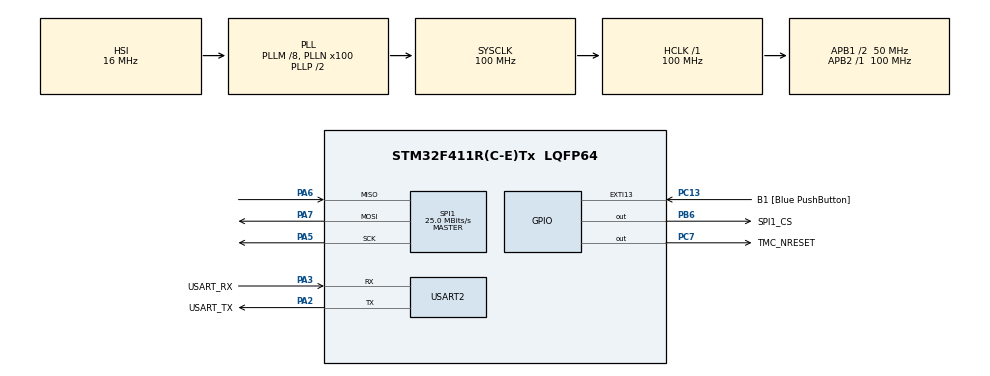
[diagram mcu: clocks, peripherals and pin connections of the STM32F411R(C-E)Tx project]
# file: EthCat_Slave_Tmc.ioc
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Dma.Request0=SPI1_RX
Dma.Request1=SPI1_TX
Dma.SPI1_RX.0.Direction=DMA_PERIPH_TO_MEMORY
Dma.SPI1_RX.0.FIFOMode=DMA_FIFOMODE_ENABLE
Dma.SPI1_RX.0.FIFOThreshold=DMA_FIFO_THRESHOLD_FULL
Dma.SPI1_RX.0.Instance=DMA2_Stream0
Dma.SPI1_RX.0.MemBurst=DMA_MBURST_SINGLE
Dma.SPI1_RX.0.MemDataAlignment=DMA_MDATAALIGN_BYTE
Dma.SPI1_RX.0.MemInc=DMA_MINC_ENABLE
Dma.SPI1_RX.0.Mode=DMA_NORMAL
Dma.SPI1_RX.0.PeriphBurst=DMA_PBURST_SINGLE
Dma.SPI1_RX.0.PeriphDataAlignment=DMA_PDATAALIGN_BYTE
Dma.SPI1_RX.0.PeriphInc=DMA_PINC_DISABLE
Dma.SPI1_RX.0.Priority=DMA_PRIORITY_HIGH
Dma.SPI1_TX.1.Direction=DMA_MEMORY_TO_PERIPH
Dma.SPI1_TX.1.FIFOMode=DMA_FIFOMODE_ENABLE
Dma.SPI1_TX.1.FIFOThreshold=DMA_FIFO_THRESHOLD_FULL
Dma.SPI1_TX.1.Instance=DMA2_Stream2
Dma.SPI1_TX.1.MemBurst=DMA_MBURST_SINGLE
Dma.SPI1_TX.1.MemDataAlignment=DMA_MDATAALIGN_BYTE
Dma.SPI1_TX.1.MemInc=DMA_MINC_ENABLE
Dma.SPI1_TX.1.Mode=DMA_NORMAL
Dma.SPI1_TX.1.PeriphBurst=DMA_PBURST_SINGLE
Dma.SPI1_TX.1.PeriphDataAlignment=DMA_PDATAALIGN_BYTE
Dma.SPI1_TX.1.PeriphInc=DMA_PINC_DISABLE
Dma.SPI1_TX.1.Priority=DMA_PRIORITY_HIGH
FREERTOS.INCLUDE_eTaskGetState=0
FREERTOS.INCLUDE_pcTaskGetTaskName=1
FREERTOS.INCLUDE_vTaskDelayUntil=1
FREERTOS.INCLUDE_xEventGroupSetBitFromISR=1
FREERTOS.INCLUDE_xTimerPendFunctionCall=1
FREERTOS.Tasks01=appTestTask,0,256,testTask,As weak,NULL,Dynamic,NULL,NULL;ethCatSlvTask,2,1024,ethCat_Task,As weak,NULL,Dynamic,NULL,NULL
FREERTOS.configCHECK_FOR_STACK_OVERFLOW=1
FREERTOS.configENABLE_FPU=1
FREERTOS.configGENERATE_RUN_TIME_STATS=1
FREERTOS.configUSE_IDLE_HOOK=1
FREERTOS.configUSE_NEWLIB_REENTRANT=1
FREERTOS.configUSE_TICKLESS_IDLE=1
FREERTOS.configUSE_TIMERS=1
Mcu.Family=STM32F4
Mcu.Name=STM32F411R(C-E)Tx
Mcu.Package=LQFP64
NVIC.DMA2_Stream0_IRQn=true\:5\:0\:false\:false\:true\:true\:false\:true\:true
NVIC.DMA2_Stream2_IRQn=true\:5\:0\:false\:false\:true\:true\:false\:true\:true
NVIC.PriorityGroup=NVIC_PRIORITYGROUP_4
NVIC.SPI1_IRQn=true\:5\:0\:false\:false\:true\:true\:true\:true\:true
NVIC.TIM1_UP_TIM10_IRQn=true\:15\:0\:false\:false\:true\:false\:false\:true\:true
NVIC.TimeBase=TIM1_UP_TIM10_IRQn
NVIC.TimeBaseIP=TIM1
PA13.GPIO_Label=TMS
PA13.Mode=Serial_Wire
PA13.Signal=SYS_JTMS-SWDIO
PA14.GPIO_Label=TCK
PA14.Mode=Serial_Wire
PA14.Signal=SYS_JTCK-SWCLK
PA2.GPIO_Label=USART_TX
PA2.Mode=Asynchronous
PA2.Signal=USART2_TX
PA3.GPIO_Label=USART_RX
PA3.Mode=Asynchronous
PA3.Signal=USART2_RX
PA5.Mode=Full_Duplex_Master
PA5.Signal=SPI1_SCK
PA6.Mode=Full_Duplex_Master
PA6.Signal=SPI1_MISO
PA7.Mode=Full_Duplex_Master
PA7.Signal=SPI1_MOSI
PB6.GPIO_Label=SPI1_CS
PB6.GPIO_PuPd=GPIO_PULLUP
PB6.GPIO_Speed=GPIO_SPEED_FREQ_LOW
PB6.Signal=GPIO_Output
PC13-ANTI_TAMP.GPIO_Label=B1 [Blue PushButton]
PC13-ANTI_TAMP.GPIO_ModeDefaultEXTI=GPIO_MODE_IT_FALLING
PC13-ANTI_TAMP.Signal=GPXTI13
PC14-OSC32_IN.Mode=LSE-External-Oscillator
PC14-OSC32_IN.Signal=RCC_OSC32_IN
PC15-OSC32_OUT.Mode=LSE-External-Oscillator
PC15-OSC32_OUT.Signal=RCC_OSC32_OUT
PC7.GPIO_Label=TMC_NRESET
PC7.GPIO_ModeDefaultOutputPP=GPIO_MODE_OUTPUT_PP
PC7.GPIO_PuPd=GPIO_PULLUP
PC7.GPIO_Speed=GPIO_SPEED_FREQ_MEDIUM
PC7.Signal=GPIO_Output
PH0\ -\ OSC_IN.Mode=HSE-External-Clock-Source
PH0\ -\ OSC_IN.Signal=RCC_OSC_IN
PH1\ -\ OSC_OUT.Mode=HSE-External-Clock-Source
PH1\ -\ OSC_OUT.Signal=RCC_OSC_OUT
ProjectManager.HeapSize=0x200
ProjectManager.StackSize=0x400
ProjectManager.TargetToolchain=STM32CubeIDE
RCC.48MHZClocksFreq_Value=50000000
RCC.AHBFreq_Value=100000000
RCC.APB1CLKDivider=RCC_HCLK_DIV2
RCC.APB1Freq_Value=50000000
RCC.APB1TimFreq_Value=100000000
RCC.APB2Freq_Value=100000000
RCC.APB2TimFreq_Value=100000000
RCC.CortexFreq_Value=100000000
RCC.FLatency-AdvancedSettings=FLASH_LATENCY_3
RCC.HCLKFreq_Value=100000000
RCC.HSE_VALUE=8000000
RCC.HSI_VALUE=16000000
RCC.PLLM=8
RCC.PLLN=100
RCC.SYSCLKFreq_VALUE=100000000
RCC.SYSCLKSource=RCC_SYSCLKSOURCE_PLLCLK
RCC.VCOOutputFreq_Value=200000000
SPI1.BaudRatePrescaler=SPI_BAUDRATEPRESCALER_4
SPI1.CLKPhase=SPI_PHASE_2EDGE
SPI1.CLKPolarity=SPI_POLARITY_HIGH
SPI1.CalculateBaudRate=25.0 MBits/s
SPI1.Direction=SPI_DIRECTION_2LINES
SPI1.Mode=SPI_MODE_MASTER
SPI1.VirtualType=VM_MASTER
USART2.VirtualMode=VM_ASYNC
VP_FREERTOS_VS_CMSIS_V1.Mode=CMSIS_V1
VP_SYS_VS_tim1.Mode=TIM1
board=NUCLEO-F411RE

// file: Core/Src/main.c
/* USER CODE BEGIN Header */
/**
  ******************************************************************************
  * @file           : main.c
  * @brief          : Main program body
  ******************************************************************************
  * @attention
  *
  * Copyright (c) 2023 STMicroelectronics.
  * All rights reserved.
  *
  * This software is licensed under terms that can be found in the LICENSE file
  * in the root directory of this software component.
  * If no LICENSE file comes with this software, it is provided AS-IS.
  *
  ******************************************************************************
  */
/* USER CODE END Header */
#include "main.h"
#include "cmsis_os.h"
#include "dma.h"
#include "spi.h"
#include "usart.h"
#include "gpio.h"

/* USER CODE BEGIN Includes */
#include "TMC8462.h"
/* USER CODE END Includes */

void SystemClock_Config(void);
void MX_FREERTOS_Init(void);

int main(void)
{

  /* MCU Configuration--------------------------------------------------------*/

  /* Reset of all peripherals, Initializes the Flash interface and the Systick. */
  HAL_Init();

  /* Configure the system clock */
  SystemClock_Config();

  /* Initialize all configured peripherals */
  MX_GPIO_Init();
  MX_DMA_Init();
  MX_SPI1_Init();
  MX_USART2_UART_Init();

  /* Call init function for freertos objects (in freertos.c) */
  MX_FREERTOS_Init();

  /* Start scheduler */
  osKernelStart();
  /* We should never get here as control is now taken by the scheduler */
  /* Infinite loop */
  while (1)
  {

  }
}

void SystemClock_Config(void)
{
  RCC_OscInitTypeDef RCC_OscInitStruct = {0};
  RCC_ClkInitTypeDef RCC_ClkInitStruct = {0};

  /** Configure the main internal regulator output voltage
  */
  __HAL_RCC_PWR_CLK_ENABLE();
  __HAL_PWR_VOLTAGESCALING_CONFIG(PWR_REGULATOR_VOLTAGE_SCALE1);

  /** Initializes the RCC Oscillators according to the specified parameters
  * in the RCC_OscInitTypeDef structure.
  */
  RCC_OscInitStruct.OscillatorType = RCC_OSCILLATORTYPE_HSI;
  RCC_OscInitStruct.HSIState = RCC_HSI_ON;
  RCC_OscInitStruct.HSICalibrationValue = RCC_HSICALIBRATION_DEFAULT;
  RCC_OscInitStruct.PLL.PLLState = RCC_PLL_ON;
  RCC_OscInitStruct.PLL.PLLSource = RCC_PLLSOURCE_HSI;
  RCC_OscInitStruct.PLL.PLLM = 8;
  RCC_OscInitStruct.PLL.PLLN = 100;
  RCC_OscInitStruct.PLL.PLLP = RCC_PLLP_DIV2;
  RCC_OscInitStruct.PLL.PLLQ = 4;
  if (HAL_RCC_OscConfig(&RCC_OscInitStruct) != HAL_OK)
  {
    Error_Handler();
  }

  /** Initializes the CPU, AHB and APB buses clocks
  */
  RCC_ClkInitStruct.ClockType = RCC_CLOCKTYPE_HCLK|RCC_CLOCKTYPE_SYSCLK
                              |RCC_CLOCKTYPE_PCLK1|RCC_CLOCKTYPE_PCLK2;
  RCC_ClkInitStruct.SYSCLKSource = RCC_SYSCLKSOURCE_PLLCLK;
  RCC_ClkInitStruct.AHBCLKDivider = RCC_SYSCLK_DIV1;
  RCC_ClkInitStruct.APB1CLKDivider = RCC_HCLK_DIV2;
  RCC_ClkInitStruct.APB2CLKDivider = RCC_HCLK_DIV1;

  if (HAL_RCC_ClockConfig(&RCC_ClkInitStruct, FLASH_LATENCY_3) != HAL_OK)
  {
    Error_Handler();
  }
}

void HAL_TIM_PeriodElapsedCallback(TIM_HandleTypeDef *htim)
{
  if (htim->Instance == TIM1) {
    HAL_IncTick();
  }
}

void Error_Handler(void)
{
  __disable_irq();
  while (1)
  {
  }
}

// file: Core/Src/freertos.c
/* USER CODE BEGIN Header */
/**
  ******************************************************************************
  * File Name          : freertos.c
  * Description        : Code for freertos applications
  ******************************************************************************
  * @attention
  *
  * Copyright (c) 2023 STMicroelectronics.
  * All rights reserved.
  *
  * This software is licensed under terms that can be found in the LICENSE file
  * in the root directory of this software component.
  * If no LICENSE file comes with this software, it is provided AS-IS.
  *
  ******************************************************************************
  */
/* USER CODE END Header */

#include "FreeRTOS.h"
#include "task.h"
#include "main.h"
#include "cmsis_os.h"

/* USER CODE BEGIN Includes */

#include "appTest.h"

/* USER CODE END Includes */

osThreadId appTestTaskHandle;
osThreadId ethCatSlvTaskHandle;

void testTask(void const * argument);
void ethCat_Task(void const * argument);

void MX_FREERTOS_Init(void); /* (MISRA C 2004 rule 8.1) */

/* GetIdleTaskMemory prototype (linked to static allocation support) */
void vApplicationGetIdleTaskMemory( StaticTask_t **ppxIdleTaskTCBBuffer, StackType_t **ppxIdleTaskStackBuffer, uint32_t *pulIdleTaskStackSize );

/* GetTimerTaskMemory prototype (linked to static allocation support) */
void vApplicationGetTimerTaskMemory( StaticTask_t **ppxTimerTaskTCBBuffer, StackType_t **ppxTimerTaskStackBuffer, uint32_t *pulTimerTaskStackSize );

/* Hook prototypes */
void configureTimerForRunTimeStats(void);
unsigned long getRunTimeCounterValue(void);
void vApplicationIdleHook(void);
void vApplicationStackOverflowHook(xTaskHandle xTask, signed char *pcTaskName);

/* USER CODE BEGIN 1 */
/* Functions needed when configGENERATE_RUN_TIME_STATS is on */
__weak void configureTimerForRunTimeStats(void)
{

}

__weak unsigned long getRunTimeCounterValue(void)
{
return 0;
}
/* USER CODE END 1 */

/* USER CODE BEGIN 2 */
__weak void vApplicationIdleHook( void )
{
   /* vApplicationIdleHook() will only be called if configUSE_IDLE_HOOK is set
   to 1 in FreeRTOSConfig.h. It will be called on each iteration of the idle
   task. It is essential that code added to this hook function never attempts
   to block in any way (for example, call xQueueReceive() with a block time
   specified, or call vTaskDelay()). If the application makes use of the
   vTaskDelete() API function (as this demo application does) then it is also
   important that vApplicationIdleHook() is permitted to return to its calling
   function, because it is the responsibility of the idle task to clean up
   memory allocated by the kernel to any task that has since been deleted. */
}
/* USER CODE END 2 */

/* USER CODE BEGIN 4 */
__weak void vApplicationStackOverflowHook(xTaskHandle xTask, signed char *pcTaskName)
{
   /* Run time stack overflow checking is performed if
   configCHECK_FOR_STACK_OVERFLOW is defined to 1 or 2. This hook function is
   called if a stack overflow is detected. */
}
/* USER CODE END 4 */

/* USER CODE BEGIN PREPOSTSLEEP */
__weak void PreSleepProcessing(uint32_t ulExpectedIdleTime)
{
/* place for user code */
}

__weak void PostSleepProcessing(uint32_t ulExpectedIdleTime)
{
/* place for user code */
}
/* USER CODE END PREPOSTSLEEP */

/* USER CODE BEGIN GET_IDLE_TASK_MEMORY */
static StaticTask_t xIdleTaskTCBBuffer;
static StackType_t xIdleStack[configMINIMAL_STACK_SIZE];

void vApplicationGetIdleTaskMemory( StaticTask_t **ppxIdleTaskTCBBuffer, StackType_t **ppxIdleTaskStackBuffer, uint32_t *pulIdleTaskStackSize )
{
  *ppxIdleTaskTCBBuffer = &xIdleTaskTCBBuffer;
  *ppxIdleTaskStackBuffer = &xIdleStack[0];
  *pulIdleTaskStackSize = configMINIMAL_STACK_SIZE;
  /* place for user code */
}
/* USER CODE END GET_IDLE_TASK_MEMORY */

/* USER CODE BEGIN GET_TIMER_TASK_MEMORY */
static StaticTask_t xTimerTaskTCBBuffer;
static StackType_t xTimerStack[configTIMER_TASK_STACK_DEPTH];

void vApplicationGetTimerTaskMemory( StaticTask_t **ppxTimerTaskTCBBuffer, StackType_t **ppxTimerTaskStackBuffer, uint32_t *pulTimerTaskStackSize )
{
  *ppxTimerTaskTCBBuffer = &xTimerTaskTCBBuffer;
  *ppxTimerTaskStackBuffer = &xTimerStack[0];
  *pulTimerTaskStackSize = configTIMER_TASK_STACK_DEPTH;
  /* place for user code */
}
/* USER CODE END GET_TIMER_TASK_MEMORY */

void MX_FREERTOS_Init(void) {
  /* USER CODE BEGIN Init */
  osThreadSuspendAll();
  /* USER CODE END Init */

  /* Create the thread(s) */
  /* definition and creation of appTestTask */
  osThreadDef(appTestTask, testTask, osPriorityNormal, 0, 256);
  appTestTaskHandle = osThreadCreate(osThread(appTestTask), NULL);

  /* definition and creation of ethCatSlvTask */
  osThreadDef(ethCatSlvTask, ethCat_Task, osPriorityHigh, 0, 1024);
  ethCatSlvTaskHandle = osThreadCreate(osThread(ethCatSlvTask), NULL);

  /* USER CODE BEGIN RTOS_THREADS */
  /* add threads, ... */
#if IS_APPTEST_RUN == 0
  osThreadTerminate (appTestTaskHandle);
#elif IS_APPTEST_RUN == 1
  osThreadTerminate (ethCatSlvTaskHandle);
#endif

  /* Resume the threads. */
  osThreadResumeAll();
  /* USER CODE END RTOS_THREADS */

}

__weak void testTask(void const * argument)
{
  for(;;)
  {
    osDelay(1);
  }
}

__weak void ethCat_Task(void const * argument)
{
  for(;;)
  {
    osDelay(1);
  }
}
